AUTOSAR XML (schema 4-0-3)
standard types defined: Boolean, UInt32, UInt8
package /AUTOSAR_Platform/DataConstrs
  range DC_Boolean: raw 0..1
package /PATAC/Facility/DataTypes/Implementation
  unit NoUnit: factor-si-to-unit=1, offset-si-to-unit=0
package /PATAC/MSM/ComponentTypes
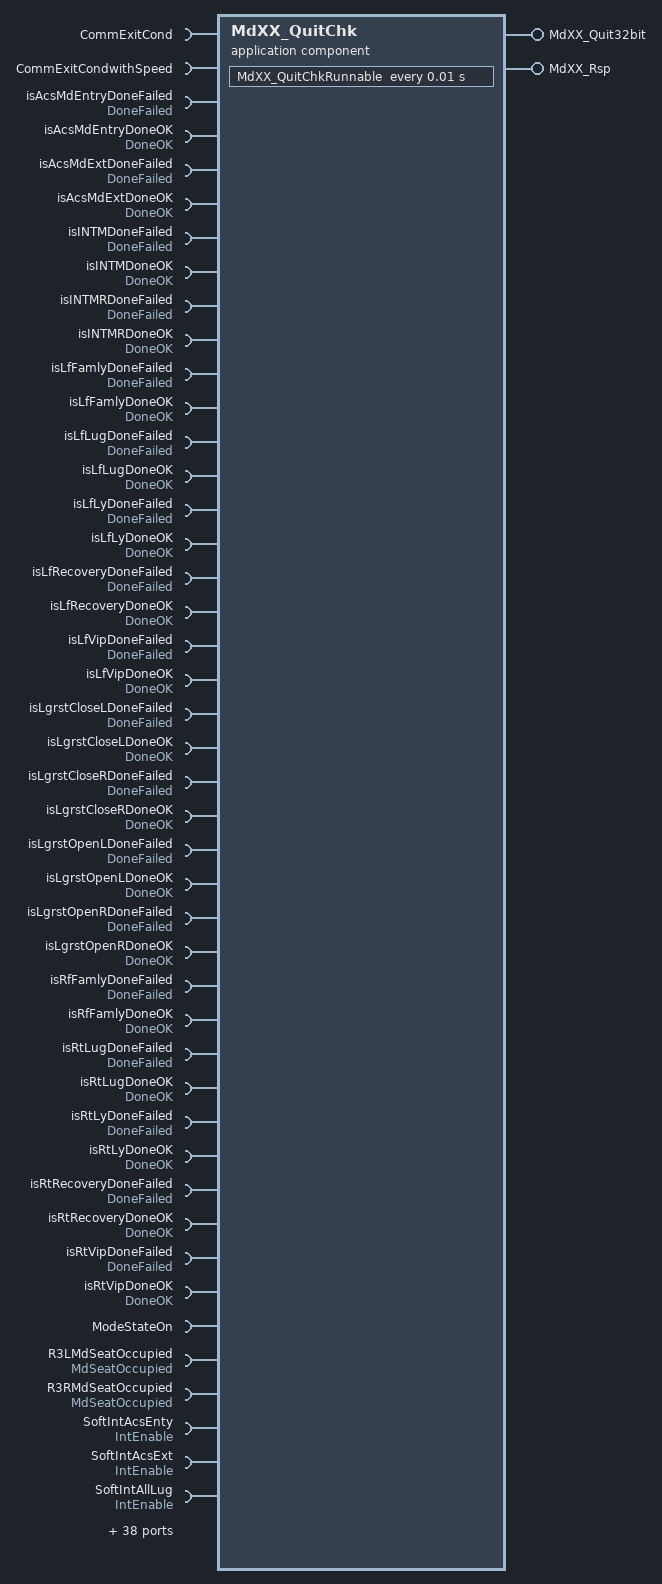
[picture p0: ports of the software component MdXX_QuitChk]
  application sw component type MdXX_QuitChk
    provide port MdXX_Quit32bit: nonqueued-sender-com-spec{data-element=MdXX_Quit32bit/Val, init-value=0}, provided-interface=MdXX_Quit32bit
    provide port MdXX_Rsp: provided-interface=MdXX_Rsp
      provided-com-specs:
        data-element=Md1_Rsp, init-value=0
        data-element=Md{10..19}_Rsp, init-value=0
        data-element=Md2_Rsp, init-value=0
        data-element=Md{20..29}_Rsp, init-value=0
        data-element=Md3_Rsp, init-value=0
        data-element=Md{30..32}_Rsp, init-value=0
        data-element=Md{4..9}_Rsp, init-value=0
    82 x require port:
      CommExitCond: nonqueued-receiver-com-spec{data-element=CommExitCond/Val, filter=data-filter-type=ALWAYS, init-value=0}, required-interface=CommExitCond
      CommExitCondwithSpeed: nonqueued-receiver-com-spec{data-element=CommExitCondwithSpeed/Val, filter=data-filter-type=ALWAYS, init-value=0}, required-interface=CommExitCondwithSpeed
      isAcsMdEntryDoneFailed: nonqueued-receiver-com-spec{data-element=DoneFailed/Val, filter=data-filter-type=ALWAYS, init-value=0}, required-interface=DoneFailed
      isAcsMdEntryDoneOK: nonqueued-receiver-com-spec{data-element=DoneOK/Val, filter=data-filter-type=ALWAYS, init-value=0}, required-interface=DoneOK
      isAcsMdExtDoneFailed: nonqueued-receiver-com-spec{data-element=DoneFailed/Val, filter=data-filter-type=ALWAYS, init-value=0}, required-interface=DoneFailed
      isAcsMdExtDoneOK: nonqueued-receiver-com-spec{data-element=DoneOK/Val, filter=data-filter-type=ALWAYS, init-value=0}, required-interface=DoneOK
      isINTMDoneFailed: nonqueued-receiver-com-spec{data-element=DoneFailed/Val, filter=data-filter-type=ALWAYS, init-value=0}, required-interface=DoneFailed
      isINTMDoneOK: nonqueued-receiver-com-spec{data-element=DoneOK/Val, filter=data-filter-type=ALWAYS, init-value=0}, required-interface=DoneOK
      isINTMRDoneFailed: nonqueued-receiver-com-spec{data-element=DoneFailed/Val, filter=data-filter-type=ALWAYS, init-value=0}, required-interface=DoneFailed
      isINTMRDoneOK: nonqueued-receiver-com-spec{data-element=DoneOK/Val, filter=data-filter-type=ALWAYS, init-value=0}, required-interface=DoneOK
      isLfFamlyDoneFailed: nonqueued-receiver-com-spec{data-element=DoneFailed/Val, filter=data-filter-type=ALWAYS, init-value=0}, required-interface=DoneFailed
      isLfFamlyDoneOK: nonqueued-receiver-com-spec{data-element=DoneOK/Val, filter=data-filter-type=ALWAYS, init-value=0}, required-interface=DoneOK
      isLfLugDoneFailed: nonqueued-receiver-com-spec{data-element=DoneFailed/Val, filter=data-filter-type=ALWAYS, init-value=0}, required-interface=DoneFailed
      isLfLugDoneOK: nonqueued-receiver-com-spec{data-element=DoneOK/Val, filter=data-filter-type=ALWAYS, init-value=0}, required-interface=DoneOK
      isLfLyDoneFailed: nonqueued-receiver-com-spec{data-element=DoneFailed/Val, filter=data-filter-type=ALWAYS, init-value=0}, required-interface=DoneFailed
      isLfLyDoneOK: nonqueued-receiver-com-spec{data-element=DoneOK/Val, filter=data-filter-type=ALWAYS, init-value=0}, required-interface=DoneOK
      isLfRecoveryDoneFailed: nonqueued-receiver-com-spec{data-element=DoneFailed/Val, filter=data-filter-type=ALWAYS, init-value=0}, required-interface=DoneFailed
      isLfRecoveryDoneOK: nonqueued-receiver-com-spec{data-element=DoneOK/Val, filter=data-filter-type=ALWAYS, init-value=0}, required-interface=DoneOK
      isLfVipDoneFailed: nonqueued-receiver-com-spec{data-element=DoneFailed/Val, filter=data-filter-type=ALWAYS, init-value=0}, required-interface=DoneFailed
      isLfVipDoneOK: nonqueued-receiver-com-spec{data-element=DoneOK/Val, filter=data-filter-type=ALWAYS, init-value=0}, required-interface=DoneOK
      isLgrstCloseLDoneFailed: nonqueued-receiver-com-spec{data-element=DoneFailed/Val, filter=data-filter-type=ALWAYS, init-value=0}, required-interface=DoneFailed
      isLgrstCloseLDoneOK: nonqueued-receiver-com-spec{data-element=DoneOK/Val, filter=data-filter-type=ALWAYS, init-value=0}, required-interface=DoneOK
      isLgrstCloseRDoneFailed: nonqueued-receiver-com-spec{data-element=DoneFailed/Val, filter=data-filter-type=ALWAYS, init-value=0}, required-interface=DoneFailed
      isLgrstCloseRDoneOK: nonqueued-receiver-com-spec{data-element=DoneOK/Val, filter=data-filter-type=ALWAYS, init-value=0}, required-interface=DoneOK
      isLgrstOpenLDoneFailed: nonqueued-receiver-com-spec{data-element=DoneFailed/Val, filter=data-filter-type=ALWAYS, init-value=0}, required-interface=DoneFailed
      isLgrstOpenLDoneOK: nonqueued-receiver-com-spec{data-element=DoneOK/Val, filter=data-filter-type=ALWAYS, init-value=0}, required-interface=DoneOK
      isLgrstOpenRDoneFailed: nonqueued-receiver-com-spec{data-element=DoneFailed/Val, filter=data-filter-type=ALWAYS, init-value=0}, required-interface=DoneFailed
      isLgrstOpenRDoneOK: nonqueued-receiver-com-spec{data-element=DoneOK/Val, filter=data-filter-type=ALWAYS, init-value=0}, required-interface=DoneOK
      isRfFamlyDoneFailed: nonqueued-receiver-com-spec{data-element=DoneFailed/Val, filter=data-filter-type=ALWAYS, init-value=0}, required-interface=DoneFailed
      isRfFamlyDoneOK: nonqueued-receiver-com-spec{data-element=DoneOK/Val, filter=data-filter-type=ALWAYS, init-value=0}, required-interface=DoneOK
      isRtLugDoneFailed: nonqueued-receiver-com-spec{data-element=DoneFailed/Val, filter=data-filter-type=ALWAYS, init-value=0}, required-interface=DoneFailed
      isRtLugDoneOK: nonqueued-receiver-com-spec{data-element=DoneOK/Val, filter=data-filter-type=ALWAYS, init-value=0}, required-interface=DoneOK
      isRtLyDoneFailed: nonqueued-receiver-com-spec{data-element=DoneFailed/Val, filter=data-filter-type=ALWAYS, init-value=0}, required-interface=DoneFailed
      isRtLyDoneOK: nonqueued-receiver-com-spec{data-element=DoneOK/Val, filter=data-filter-type=ALWAYS, init-value=0}, required-interface=DoneOK
      isRtRecoveryDoneFailed: nonqueued-receiver-com-spec{data-element=DoneFailed/Val, filter=data-filter-type=ALWAYS, init-value=0}, required-interface=DoneFailed
      isRtRecoveryDoneOK: nonqueued-receiver-com-spec{data-element=DoneOK/Val, filter=data-filter-type=ALWAYS, init-value=0}, required-interface=DoneOK
      isRtVipDoneFailed: nonqueued-receiver-com-spec{data-element=DoneFailed/Val, filter=data-filter-type=ALWAYS, init-value=0}, required-interface=DoneFailed
      isRtVipDoneOK: nonqueued-receiver-com-spec{data-element=DoneOK/Val, filter=data-filter-type=ALWAYS, init-value=0}, required-interface=DoneOK
      ModeStateOn: nonqueued-receiver-com-spec{data-element=ModeStateOn/Val, filter=data-filter-type=ALWAYS, init-value=0}, required-interface=ModeStateOn
      R3LMdSeatOccupied: nonqueued-receiver-com-spec{data-element=MdSeatOccupied/Val, filter=data-filter-type=ALWAYS, init-value=0}, required-interface=MdSeatOccupied
      R3RMdSeatOccupied: nonqueued-receiver-com-spec{data-element=MdSeatOccupied/Val, filter=data-filter-type=ALWAYS, init-value=0}, required-interface=MdSeatOccupied
      SoftIntAcsEnty: nonqueued-receiver-com-spec{data-element=IntEnable/Val, filter=data-filter-type=ALWAYS, init-value=0}, required-interface=IntEnable
      SoftIntAcsExt: nonqueued-receiver-com-spec{data-element=IntEnable/Val, filter=data-filter-type=ALWAYS, init-value=0}, required-interface=IntEnable
      SoftIntAllLug: nonqueued-receiver-com-spec{data-element=IntEnable/Val, filter=data-filter-type=ALWAYS, init-value=0}, required-interface=IntEnable
      SoftIntAllVip: nonqueued-receiver-com-spec{data-element=IntEnable/Val, filter=data-filter-type=ALWAYS, init-value=0}, required-interface=IntEnable
      SoftIntIntimacyRt: nonqueued-receiver-com-spec{data-element=IntEnable/Val, filter=data-filter-type=ALWAYS, init-value=0}, required-interface=IntEnable
      SoftIntINTM: nonqueued-receiver-com-spec{data-element=IntEnable/Val, filter=data-filter-type=ALWAYS, init-value=0}, required-interface=IntEnable
      SoftIntLfFamly: nonqueued-receiver-com-spec{data-element=IntEnable/Val, filter=data-filter-type=ALWAYS, init-value=0}, required-interface=IntEnable
      SoftIntLfLug: nonqueued-receiver-com-spec{data-element=IntEnable/Val, filter=data-filter-type=ALWAYS, init-value=0}, required-interface=IntEnable
      SoftIntLfLy: nonqueued-receiver-com-spec{data-element=IntEnable/Val, filter=data-filter-type=ALWAYS, init-value=0}, required-interface=IntEnable
      SoftIntLfRcvy: nonqueued-receiver-com-spec{data-element=IntEnable/Val, filter=data-filter-type=ALWAYS, init-value=0}, required-interface=IntEnable
      SoftIntLfVip: nonqueued-receiver-com-spec{data-element=IntEnable/Val, filter=data-filter-type=ALWAYS, init-value=0}, required-interface=IntEnable
      SoftIntLgrstCloseLt: nonqueued-receiver-com-spec{data-element=IntEnable/Val, filter=data-filter-type=ALWAYS, init-value=0}, required-interface=IntEnable
      SoftIntLgrstCloseRt: nonqueued-receiver-com-spec{data-element=IntEnable/Val, filter=data-filter-type=ALWAYS, init-value=0}, required-interface=IntEnable
      SoftIntLgrstOpenLt: nonqueued-receiver-com-spec{data-element=IntEnable/Val, filter=data-filter-type=ALWAYS, init-value=0}, required-interface=IntEnable
      SoftIntLgrstOpenRt: nonqueued-receiver-com-spec{data-element=IntEnable/Val, filter=data-filter-type=ALWAYS, init-value=0}, required-interface=IntEnable
      SoftIntRtFamly: nonqueued-receiver-com-spec{data-element=IntEnable/Val, filter=data-filter-type=ALWAYS, init-value=0}, required-interface=IntEnable
      SoftIntRtLug: nonqueued-receiver-com-spec{data-element=IntEnable/Val, filter=data-filter-type=ALWAYS, init-value=0}, required-interface=IntEnable
      SoftIntRtLy: nonqueued-receiver-com-spec{data-element=IntEnable/Val, filter=data-filter-type=ALWAYS, init-value=0}, required-interface=IntEnable
      SoftIntRtRcvy: nonqueued-receiver-com-spec{data-element=IntEnable/Val, filter=data-filter-type=ALWAYS, init-value=0}, required-interface=IntEnable
      SoftIntRtVip: nonqueued-receiver-com-spec{data-element=IntEnable/Val, filter=data-filter-type=ALWAYS, init-value=0}, required-interface=IntEnable
      StNumFlg: required-interface=StNumFlg
        required-com-specs:
          data-element=Is4s, filter=data-filter-type=ALWAYS, init-value=0
          data-element=Is6s, filter=data-filter-type=ALWAYS, init-value=0
          data-element=Is6s7s, filter=data-filter-type=ALWAYS, init-value=0
          data-element=Is7s, filter=data-filter-type=ALWAYS, init-value=0
      SwIntAcsEnty: nonqueued-receiver-com-spec{data-element=IntEnable/Val, filter=data-filter-type=ALWAYS, init-value=0}, required-interface=IntEnable
      SwIntAcsExt: nonqueued-receiver-com-spec{data-element=IntEnable/Val, filter=data-filter-type=ALWAYS, init-value=0}, required-interface=IntEnable
      SwIntAllLug: nonqueued-receiver-com-spec{data-element=IntEnable/Val, filter=data-filter-type=ALWAYS, init-value=0}, required-interface=IntEnable
      SwIntAllVip: nonqueued-receiver-com-spec{data-element=IntEnable/Val, filter=data-filter-type=ALWAYS, init-value=0}, required-interface=IntEnable
      SwIntIntimacyRt: nonqueued-receiver-com-spec{data-element=IntEnable/Val, filter=data-filter-type=ALWAYS, init-value=0}, required-interface=IntEnable
      SwIntINTM: nonqueued-receiver-com-spec{data-element=IntEnable/Val, filter=data-filter-type=ALWAYS, init-value=0}, required-interface=IntEnable
      SwIntLfFamly: nonqueued-receiver-com-spec{data-element=IntEnable/Val, filter=data-filter-type=ALWAYS, init-value=0}, required-interface=IntEnable
      SwIntLfLug: nonqueued-receiver-com-spec{data-element=IntEnable/Val, filter=data-filter-type=ALWAYS, init-value=0}, required-interface=IntEnable
      SwIntLfLy: nonqueued-receiver-com-spec{data-element=IntEnable/Val, filter=data-filter-type=ALWAYS, init-value=0}, required-interface=IntEnable
      SwIntLfRcvy: nonqueued-receiver-com-spec{data-element=IntEnable/Val, filter=data-filter-type=ALWAYS, init-value=0}, required-interface=IntEnable
      SwIntLfVip: nonqueued-receiver-com-spec{data-element=IntEnable/Val, filter=data-filter-type=ALWAYS, init-value=0}, required-interface=IntEnable
      SwIntLgrstCloseLt: nonqueued-receiver-com-spec{data-element=IntEnable/Val, filter=data-filter-type=ALWAYS, init-value=0}, required-interface=IntEnable
      SwIntLgrstCloseRt: nonqueued-receiver-com-spec{data-element=IntEnable/Val, filter=data-filter-type=ALWAYS, init-value=0}, required-interface=IntEnable
      SwIntLgrstOpenLt: nonqueued-receiver-com-spec{data-element=IntEnable/Val, filter=data-filter-type=ALWAYS, init-value=0}, required-interface=IntEnable
      SwIntLgrstOpenRt: nonqueued-receiver-com-spec{data-element=IntEnable/Val, filter=data-filter-type=ALWAYS, init-value=0}, required-interface=IntEnable
      SwIntRtFamly: nonqueued-receiver-com-spec{data-element=IntEnable/Val, filter=data-filter-type=ALWAYS, init-value=0}, required-interface=IntEnable
      SwIntRtLug: nonqueued-receiver-com-spec{data-element=IntEnable/Val, filter=data-filter-type=ALWAYS, init-value=0}, required-interface=IntEnable
      SwIntRtLy: nonqueued-receiver-com-spec{data-element=IntEnable/Val, filter=data-filter-type=ALWAYS, init-value=0}, required-interface=IntEnable
      SwIntRtRcvy: nonqueued-receiver-com-spec{data-element=IntEnable/Val, filter=data-filter-type=ALWAYS, init-value=0}, required-interface=IntEnable
      SwIntRtVip: nonqueued-receiver-com-spec{data-element=IntEnable/Val, filter=data-filter-type=ALWAYS, init-value=0}, required-interface=IntEnable
    behavior MdXX_QuitChk_InternalBehavior
      timing event TMT_EZEBsyChkRunnable: start-on-event=MdXX_QuitChkRunnable, period=0.01
      runnable MdXX_QuitChkRunnable
        data-receive-point-by-arguments:
          85 x access:
            REC_CommExitCond_Val: accessed-variable=CommExitCond.Val
            REC_CommExitCondwithSpeed_Val: accessed-variable=CommExitCondwithSpeed.Val
            REC_isAcsMdEntryDoneFailed_Val: accessed-variable=isAcsMdEntryDoneFailed.Val
            REC_isAcsMdEntryDoneOK_Val: accessed-variable=isAcsMdEntryDoneOK.Val
            REC_isAcsMdExtDoneFailed_Val: accessed-variable=isAcsMdExtDoneFailed.Val
            REC_isAcsMdExtDoneOK_Val: accessed-variable=isAcsMdExtDoneOK.Val
            REC_isINTMDoneFailed_Val: accessed-variable=isINTMDoneFailed.Val
            REC_isINTMDoneOK_Val: accessed-variable=isINTMDoneOK.Val
            REC_isINTMRDoneFailed_Val: accessed-variable=isINTMRDoneFailed.Val
            REC_isINTMRDoneOK_Val: accessed-variable=isINTMRDoneOK.Val
            REC_isLfFamlyDoneFailed_Val: accessed-variable=isLfFamlyDoneFailed.Val
            REC_isLfFamlyDoneOK_Val: accessed-variable=isLfFamlyDoneOK.Val
            REC_isLfLugDoneFailed_Val: accessed-variable=isLfLugDoneFailed.Val
            REC_isLfLugDoneOK_Val: accessed-variable=isLfLugDoneOK.Val
            REC_isLfLyDoneFailed_Val: accessed-variable=isLfLyDoneFailed.Val
            REC_isLfLyDoneOK_Val: accessed-variable=isLfLyDoneOK.Val
            REC_isLfRecoveryDoneFailed_Val: accessed-variable=isLfRecoveryDoneFailed.Val
            REC_isLfRecoveryDoneOK_Val: accessed-variable=isLfRecoveryDoneOK.Val
            REC_isLfVipDoneFailed_Val: accessed-variable=isLfVipDoneFailed.Val
            REC_isLfVipDoneOK_Val: accessed-variable=isLfVipDoneOK.Val
            REC_isLgrstCloseLDoneFailed_Val: accessed-variable=isLgrstCloseLDoneFailed.Val
            REC_isLgrstCloseLDoneOK_Val: accessed-variable=isLgrstCloseLDoneOK.Val
            REC_isLgrstCloseRDoneFailed_Val: accessed-variable=isLgrstCloseRDoneFailed.Val
            REC_isLgrstCloseRDoneOK_Val: accessed-variable=isLgrstCloseRDoneOK.Val
            REC_isLgrstOpenLDoneFailed_Val: accessed-variable=isLgrstOpenLDoneFailed.Val
            REC_isLgrstOpenLDoneOK_Val: accessed-variable=isLgrstOpenLDoneOK.Val
            REC_isLgrstOpenRDoneFailed_Val: accessed-variable=isLgrstOpenRDoneFailed.Val
            REC_isLgrstOpenRDoneOK_Val: accessed-variable=isLgrstOpenRDoneOK.Val
            REC_isRfFamlyDoneFailed_Val: accessed-variable=isRfFamlyDoneFailed.Val
            REC_isRfFamlyDoneOK_Val: accessed-variable=isRfFamlyDoneOK.Val
            REC_isRtLugDoneFailed_Val: accessed-variable=isRtLugDoneFailed.Val
            REC_isRtLugDoneOK_Val: accessed-variable=isRtLugDoneOK.Val
            REC_isRtLyDoneFailed_Val: accessed-variable=isRtLyDoneFailed.Val
            REC_isRtLyDoneOK_Val: accessed-variable=isRtLyDoneOK.Val
            REC_isRtRecoveryDoneFailed_Val: accessed-variable=isRtRecoveryDoneFailed.Val
            REC_isRtRecoveryDoneOK_Val: accessed-variable=isRtRecoveryDoneOK.Val
            REC_isRtVipDoneFailed_Val: accessed-variable=isRtVipDoneFailed.Val
            REC_isRtVipDoneOK_Val: accessed-variable=isRtVipDoneOK.Val
            REC_ModeStateOn_Val: accessed-variable=ModeStateOn.Val
            REC_R3LMdSeatOccupied_Val: accessed-variable=R3LMdSeatOccupied.Val
            REC_R3RMdSeatOccupied_Val: accessed-variable=R3RMdSeatOccupied.Val
            REC_SoftIntAcsEnty_Val: accessed-variable=SoftIntAcsEnty.Val
            REC_SoftIntAcsExt_Val: accessed-variable=SoftIntAcsExt.Val
            REC_SoftIntAllLug_Val: accessed-variable=SoftIntAllLug.Val
            REC_SoftIntAllVip_Val: accessed-variable=SoftIntAllVip.Val
            REC_SoftIntIntimacyRt_Val: accessed-variable=SoftIntIntimacyRt.Val
            REC_SoftIntINTM_Val: accessed-variable=SoftIntINTM.Val
            REC_SoftIntLfFamly_Val: accessed-variable=SoftIntLfFamly.Val
            REC_SoftIntLfLug_Val: accessed-variable=SoftIntLfLug.Val
            REC_SoftIntLfLy_Val: accessed-variable=SoftIntLfLy.Val
            REC_SoftIntLfRcvy_Val: accessed-variable=SoftIntLfRcvy.Val
            REC_SoftIntLfVip_Val: accessed-variable=SoftIntLfVip.Val
            REC_SoftIntLgrstCloseLt_Val: accessed-variable=SoftIntLgrstCloseLt.Val
            REC_SoftIntLgrstCloseRt_Val: accessed-variable=SoftIntLgrstCloseRt.Val
            REC_SoftIntLgrstOpenLt_Val: accessed-variable=SoftIntLgrstOpenLt.Val
            REC_SoftIntLgrstOpenRt_Val: accessed-variable=SoftIntLgrstOpenRt.Val
            REC_SoftIntRtFamly_Val: accessed-variable=SoftIntRtFamly.Val
            REC_SoftIntRtLug_Val: accessed-variable=SoftIntRtLug.Val
            REC_SoftIntRtLy_Val: accessed-variable=SoftIntRtLy.Val
            REC_SoftIntRtRcvy_Val: accessed-variable=SoftIntRtRcvy.Val
            REC_SoftIntRtVip_Val: accessed-variable=SoftIntRtVip.Val
            REC_StNumFlg_Is4s: accessed-variable=StNumFlg.Is4s
            REC_StNumFlg_Is6s: accessed-variable=StNumFlg.Is6s
            REC_StNumFlg_Is6s7s: accessed-variable=StNumFlg.Is6s7s
            REC_StNumFlg_Is7s: accessed-variable=StNumFlg.Is7s
            REC_SwIntAcsEnty_Val: accessed-variable=SwIntAcsEnty.Val
            REC_SwIntAcsExt_Val: accessed-variable=SwIntAcsExt.Val
            REC_SwIntAllLug_Val: accessed-variable=SwIntAllLug.Val
            REC_SwIntAllVip_Val: accessed-variable=SwIntAllVip.Val
            REC_SwIntIntimacyRt_Val: accessed-variable=SwIntIntimacyRt.Val
            REC_SwIntINTM_Val: accessed-variable=SwIntINTM.Val
            REC_SwIntLfFamly_Val: accessed-variable=SwIntLfFamly.Val
            REC_SwIntLfLug_Val: accessed-variable=SwIntLfLug.Val
            REC_SwIntLfLy_Val: accessed-variable=SwIntLfLy.Val
            REC_SwIntLfRcvy_Val: accessed-variable=SwIntLfRcvy.Val
            REC_SwIntLfVip_Val: accessed-variable=SwIntLfVip.Val
            REC_SwIntLgrstCloseLt_Val: accessed-variable=SwIntLgrstCloseLt.Val
            REC_SwIntLgrstCloseRt_Val: accessed-variable=SwIntLgrstCloseRt.Val
            REC_SwIntLgrstOpenLt_Val: accessed-variable=SwIntLgrstOpenLt.Val
            REC_SwIntLgrstOpenRt_Val: accessed-variable=SwIntLgrstOpenRt.Val
            REC_SwIntRtFamly_Val: accessed-variable=SwIntRtFamly.Val
            REC_SwIntRtLug_Val: accessed-variable=SwIntRtLug.Val
            REC_SwIntRtLy_Val: accessed-variable=SwIntRtLy.Val
            REC_SwIntRtRcvy_Val: accessed-variable=SwIntRtRcvy.Val
            REC_SwIntRtVip_Val: accessed-variable=SwIntRtVip.Val
        data-send-points:
          33 x access:
            SEND_MdXX_Rsp_Md1_Rsp: accessed-variable=MdXX_Rsp.Md1_Rsp
            SEND_MdXX_Rsp_Md{10..19}_Rsp: accessed-variable=MdXX_Rsp.Md{10..19}_Rsp
            SEND_MdXX_Rsp_Md2_Rsp: accessed-variable=MdXX_Rsp.Md2_Rsp
            SEND_MdXX_Rsp_Md{20..29}_Rsp: accessed-variable=MdXX_Rsp.Md{20..29}_Rsp
            SEND_MdXX_Rsp_Md3_Rsp: accessed-variable=MdXX_Rsp.Md3_Rsp
            SEND_MdXX_Rsp_Md{30..32}_Rsp: accessed-variable=MdXX_Rsp.Md{30..32}_Rsp
            SEND_MdXX_Rsp_Md{4..9}_Rsp: accessed-variable=MdXX_Rsp.Md{4..9}_Rsp
            SEND_MdXXQuit32bit_Val: accessed-variable=MdXX_Quit32bit.Val
  swc implementation MdXX_QuitChk_Implementation: behavior=MdXX_QuitChk_InternalBehavior
    code-descriptors:
      code Default: artifact-descriptors=autosar-engineering-object={short-label=Default, category=SWSRC}
package /PATAC/MSM/DataTypes/ImplementationDataTypes
  impl type IntEnable: category=VALUE, base-type=Boolean, sw-calibration-access=READ-ONLY, type-emitter=RTE
package /PATAC/MSM/ModeAdjust/DataType
  impl type MdRspLocal2: category=VALUE, base-type=UInt8, sw-calibration-access=READ-ONLY, compu {0=MdRsp_None, 1=MdRsp_RecallSuccessfully, 2=MdRsp_RecallUnsuccessfully_LocalInterrupt, 3=MdRsp_RecallUnsuccessfully_NonEnghSpace, 4=MdRsp_RecallOngoing, 5=MdRsp_TargetPositionAlready, 6=MdRsp_LowPower, 7=MdRsp_CrashStat, 8=MdRsp_ThdRwOccupt, 9=MdRsp_PosNotLrn, 10=MdRsp_NotParkStat, 11=MdRsp_SpdNotCorrt}, type-emitter=RTE
package /PATAC/MSM/ModeAdjust/PortInterface
  10 x sender receiver interface:
    CommExitCond: invalidation-policy{data-element=CommExitCond/Val, handle-invalid=DONT-INVALIDATE}
      data Val: type=Boolean
    CommExitCondwithSpeed: invalidation-policy{data-element=CommExitCondwithSpeed/Val, handle-invalid=DONT-INVALIDATE}
      data Val: type=Boolean
    DoneFailed: invalidation-policy{data-element=DoneFailed/Val, handle-invalid=DONT-INVALIDATE}
      data Val: type=Boolean
    DoneOK: invalidation-policy{data-element=DoneOK/Val, handle-invalid=DONT-INVALIDATE}
      data Val: type=Boolean
    IntEnable: invalidation-policy{data-element=IntEnable/Val, handle-invalid=DONT-INVALIDATE}
      data Val: type=IntEnable
    MdSeatOccupied: invalidation-policy{data-element=MdSeatOccupied/Val, handle-invalid=DONT-INVALIDATE}
      data Val: type=Boolean
    MdXX_Quit32bit: invalidation-policy{data-element=MdXX_Quit32bit/Val, handle-invalid=DONT-INVALIDATE}
      data Val: type=UInt32
    MdXX_Rsp
      32 x data, all with type=MdRspLocal2:
        Md1_Rsp
        Md{10..19}_Rsp
        Md2_Rsp
        Md{20..29}_Rsp
        Md3_Rsp
        Md{30..32}_Rsp
        Md{4..9}_Rsp
      invalidation-policys:
        data-element=Md1_Rsp, handle-invalid=DONT-INVALIDATE
        data-element=Md2_Rsp, handle-invalid=DONT-INVALIDATE
        data-element=Md5_Rsp, handle-invalid=DONT-INVALIDATE
        data-element=Md3_Rsp, handle-invalid=DONT-INVALIDATE
        data-element=Md7_Rsp, handle-invalid=DONT-INVALIDATE
        data-element=Md4_Rsp, handle-invalid=DONT-INVALIDATE
        data-element=Md6_Rsp, handle-invalid=DONT-INVALIDATE
        data-element=Md9_Rsp, handle-invalid=DONT-INVALIDATE
        data-element=Md8_Rsp, handle-invalid=DONT-INVALIDATE
        data-element=Md11_Rsp, handle-invalid=DONT-INVALIDATE
        data-element=Md10_Rsp, handle-invalid=DONT-INVALIDATE
        data-element=Md13_Rsp, handle-invalid=DONT-INVALIDATE
        data-element=Md12_Rsp, handle-invalid=DONT-INVALIDATE
        data-element=Md21_Rsp, handle-invalid=DONT-INVALIDATE
        data-element=Md14_Rsp, handle-invalid=DONT-INVALIDATE
        data-element=Md20_Rsp, handle-invalid=DONT-INVALIDATE
        data-element=Md15_Rsp, handle-invalid=DONT-INVALIDATE
        data-element=Md19_Rsp, handle-invalid=DONT-INVALIDATE
        data-element=Md16_Rsp, handle-invalid=DONT-INVALIDATE
        data-element=Md23_Rsp, handle-invalid=DONT-INVALIDATE
        data-element=Md17_Rsp, handle-invalid=DONT-INVALIDATE
        data-element=Md22_Rsp, handle-invalid=DONT-INVALIDATE
        data-element=Md18_Rsp, handle-invalid=DONT-INVALIDATE
        data-element=Md28_Rsp, handle-invalid=DONT-INVALIDATE
        data-element=Md24_Rsp, handle-invalid=DONT-INVALIDATE
        data-element=Md30_Rsp, handle-invalid=DONT-INVALIDATE
        data-element=Md25_Rsp, handle-invalid=DONT-INVALIDATE
        data-element=Md29_Rsp, handle-invalid=DONT-INVALIDATE
        data-element=Md26_Rsp, handle-invalid=DONT-INVALIDATE
        data-element=Md31_Rsp, handle-invalid=DONT-INVALIDATE
        data-element=Md32_Rsp, handle-invalid=DONT-INVALIDATE
        data-element=Md27_Rsp, handle-invalid=DONT-INVALIDATE
    ModeStateOn: invalidation-policy{data-element=ModeStateOn/Val, handle-invalid=DONT-INVALIDATE}
      data Val: type=Boolean
    StNumFlg
      4 x data, all with type=Boolean:
        Is4s
        Is6s
        Is6s7s
        Is7s
      invalidation-policys:
        data-element=Is7s, handle-invalid=DONT-INVALIDATE
        data-element=Is6s, handle-invalid=DONT-INVALIDATE
        data-element=Is4s, handle-invalid=DONT-INVALIDATE
        data-element=Is6s7s, handle-invalid=DONT-INVALIDATE
